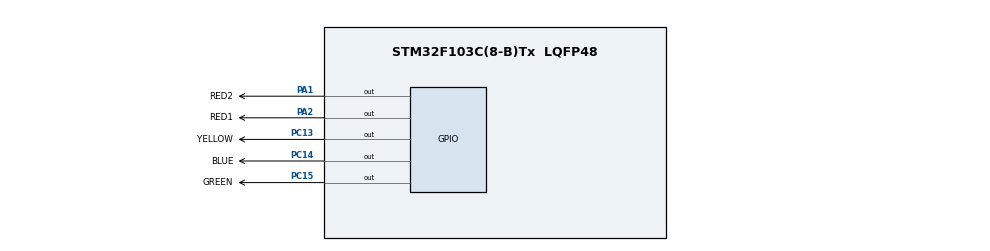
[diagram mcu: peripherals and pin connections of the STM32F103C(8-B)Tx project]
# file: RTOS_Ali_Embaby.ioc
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Mcu.Family=STM32F1
Mcu.Name=STM32F103C(8-B)Tx
Mcu.Package=LQFP48
NVIC.PriorityGroup=NVIC_PRIORITYGROUP_4
PA1.GPIO_Label=RED2
PA1.GPIO_PuPd=GPIO_PULLDOWN
PA1.Signal=GPIO_Output
PA13.Mode=Serial_Wire
PA13.Signal=SYS_JTMS-SWDIO
PA14.Mode=Serial_Wire
PA14.Signal=SYS_JTCK-SWCLK
PA2.GPIO_Label=RED1
PA2.GPIO_PuPd=GPIO_PULLDOWN
PA2.Signal=GPIO_Output
PC13-TAMPER-RTC.GPIO_Label=YELLOW
PC13-TAMPER-RTC.GPIO_PuPd=GPIO_PULLDOWN
PC13-TAMPER-RTC.Signal=GPIO_Output
PC14-OSC32_IN.GPIO_Label=BLUE
PC14-OSC32_IN.GPIO_PuPd=GPIO_PULLDOWN
PC14-OSC32_IN.Signal=GPIO_Output
PC15-OSC32_OUT.GPIO_Label=GREEN
PC15-OSC32_OUT.GPIO_PuPd=GPIO_PULLDOWN
PC15-OSC32_OUT.Signal=GPIO_Output
PD0-OSC_IN.Mode=HSE-External-Oscillator
PD0-OSC_IN.Signal=RCC_OSC_IN
PD1-OSC_OUT.Mode=HSE-External-Oscillator
PD1-OSC_OUT.Signal=RCC_OSC_OUT
ProjectManager.HeapSize=0x200
ProjectManager.StackSize=0x400
ProjectManager.TargetToolchain=STM32CubeIDE
RCC.APB1Freq_Value=8000000
RCC.APB2Freq_Value=8000000
board=custom

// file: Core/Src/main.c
/* USER CODE BEGIN Header */
/**
 ******************************************************************************
 * @file           : main.c
 * @brief          : Main program body
 ******************************************************************************
 * @attention
 *
 * <h2><center>&copy; Copyright (c) 2023 STMicroelectronics.
 * All rights reserved.</center></h2>
 *
 * This software component is licensed by ST under BSD 3-Clause license,
 * the "License"; You may not use this file except in compliance with the
 * License. You may obtain a copy of the License at:
 *                        opensource.org/licenses/BSD-3-Clause
 *
 ******************************************************************************
 */
/* USER CODE END Header */
#include "main.h"

void SystemClock_Config(void);
static void MX_GPIO_Init(void);

/* USER CODE BEGIN 0 */
uint8_t Tick_Counts = 0;
typedef struct {
	uint8_t periodicety;
	void (*fptr)(void);
} Task;
/* USER CODE END 0 */
#define NO_OF_TASKS 3
Task arr[NO_OF_TASKS];

void TASKS_CREATE(uint8_t priority, uint8_t periodicety, void (*Fptr)(void)) {
	arr[priority].periodicety = periodicety;
	arr[priority].fptr = Fptr;
}

void RedTask(void) {

	HAL_GPIO_TogglePin(RED1_GPIO_Port, RED1_Pin);

}

void BlueTask(void) {

	HAL_GPIO_TogglePin(BLUE_GPIO_Port, BLUE_Pin);

}

void GreenTask(void) {

	HAL_GPIO_TogglePin(GREEN_GPIO_Port, GREEN_Pin);

}
void SCHEDULER(void) {
	uint8_t i;
	for (i = 0; i < NO_OF_TASKS; i++) {
		if (Tick_Counts % arr[i].periodicety == 0) {
			arr[i].fptr();
		} else {

		}
	}
}
int main(void) {

	/* MCU Configuration--------------------------------------------------------*/

	/* Reset of all peripherals, Initializes the Flash interface and the Systick. */
	HAL_Init();

	/* Configure the system clock */
	SystemClock_Config();

	/* Initialize all configured peripherals */
	MX_GPIO_Init();
	HAL_SYSTICK_CLKSourceConfig(SYSTICK_CLKSOURCE_HCLK);
	HAL_SYSTICK_Config(HAL_RCC_GetHCLKFreq() / 1);
	/* USER CODE END 2 */
	TASKS_CREATE(0, 1, RedTask);
	TASKS_CREATE(1, 2, GreenTask);
	TASKS_CREATE(2, 5, BlueTask);
	/* Infinite loop */
	while (1) {

	}
}
void SysTick_Handler(void) {
	Tick_Counts++;
	SCHEDULER();
	if(Tick_Counts == 255){
		Tick_Counts = 0;
	}
}
void SystemClock_Config(void) {
	RCC_OscInitTypeDef RCC_OscInitStruct = { 0 };
	RCC_ClkInitTypeDef RCC_ClkInitStruct = { 0 };

	/** Initializes the RCC Oscillators according to the specified parameters
	 * in the RCC_OscInitTypeDef structure.
	 */
	RCC_OscInitStruct.OscillatorType = RCC_OSCILLATORTYPE_HSI;
	RCC_OscInitStruct.HSIState = RCC_HSI_ON;
	RCC_OscInitStruct.HSICalibrationValue = RCC_HSICALIBRATION_DEFAULT;
	RCC_OscInitStruct.PLL.PLLState = RCC_PLL_NONE;
	if (HAL_RCC_OscConfig(&RCC_OscInitStruct) != HAL_OK) {
		Error_Handler();
	}
	/** Initializes the CPU, AHB and APB buses clocks
	 */
	RCC_ClkInitStruct.ClockType = RCC_CLOCKTYPE_HCLK | RCC_CLOCKTYPE_SYSCLK
			| RCC_CLOCKTYPE_PCLK1 | RCC_CLOCKTYPE_PCLK2;
	RCC_ClkInitStruct.SYSCLKSource = RCC_SYSCLKSOURCE_HSI;
	RCC_ClkInitStruct.AHBCLKDivider = RCC_SYSCLK_DIV1;
	RCC_ClkInitStruct.APB1CLKDivider = RCC_HCLK_DIV1;
	RCC_ClkInitStruct.APB2CLKDivider = RCC_HCLK_DIV1;

	if (HAL_RCC_ClockConfig(&RCC_ClkInitStruct, FLASH_LATENCY_0) != HAL_OK) {
		Error_Handler();
	}
}

static void MX_GPIO_Init(void) {
	GPIO_InitTypeDef GPIO_InitStruct = { 0 };

	/* GPIO Ports Clock Enable */
	__HAL_RCC_GPIOC_CLK_ENABLE();
	__HAL_RCC_GPIOD_CLK_ENABLE();
	__HAL_RCC_GPIOA_CLK_ENABLE();

	/*Configure GPIO pin Output Level */
	HAL_GPIO_WritePin(GPIOC, YELLOW_Pin | BLUE_Pin | GREEN_Pin, GPIO_PIN_RESET);

	/*Configure GPIO pin Output Level */
	HAL_GPIO_WritePin(GPIOA, RED2_Pin | RED1_Pin, GPIO_PIN_RESET);

	/*Configure GPIO pins : YELLOW_Pin BLUE_Pin GREEN_Pin */
	GPIO_InitStruct.Pin = YELLOW_Pin | BLUE_Pin | GREEN_Pin;
	GPIO_InitStruct.Mode = GPIO_MODE_OUTPUT_PP;
	GPIO_InitStruct.Pull = GPIO_PULLDOWN;
	GPIO_InitStruct.Speed = GPIO_SPEED_FREQ_LOW;
	HAL_GPIO_Init(GPIOC, &GPIO_InitStruct);

	/*Configure GPIO pins : RED2_Pin RED1_Pin */
	GPIO_InitStruct.Pin = RED2_Pin | RED1_Pin;
	GPIO_InitStruct.Mode = GPIO_MODE_OUTPUT_PP;
	GPIO_InitStruct.Pull = GPIO_PULLDOWN;
	GPIO_InitStruct.Speed = GPIO_SPEED_FREQ_LOW;
	HAL_GPIO_Init(GPIOA, &GPIO_InitStruct);

}

void Error_Handler(void) {
}

/************************ (C) COPYRIGHT STMicroelectronics *****END OF FILE****/
